# VIMS register map
Vendor: Texas Instruments
Peripheral module from a debugger description file (folder CC23x0R5).
Registers are 32-bit, access per field, reset 0x7 unless marked. A register's access mark holds for its fields unless they carry their own. Offsets are as the file gives them; lines under a group give offsets from that group; [hi:lo] are bit positions; {n}, {i} and the like mark numbered series; 'fields as' and 'values as' point back to an identical list; <NAME> marks a mode.

## VIMS — VIMS (Versatile Instruction Memory System) All registers in this module are retained, unless explicitely mentioned.
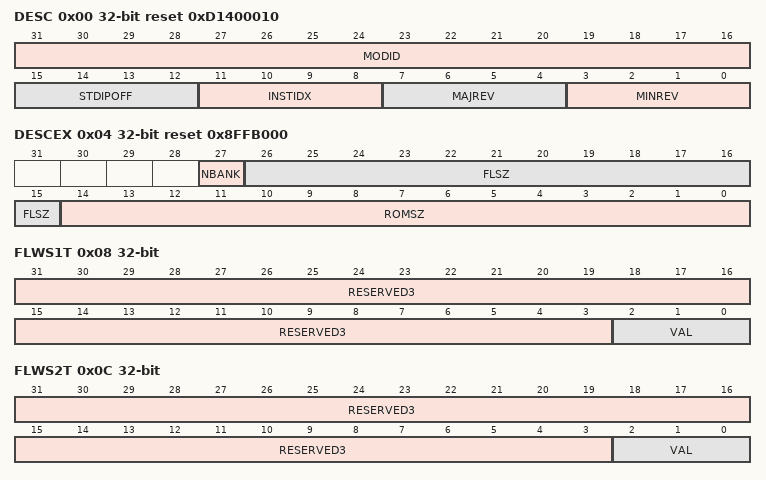
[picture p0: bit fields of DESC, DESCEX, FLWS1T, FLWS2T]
0x00 DESC ro reset 0xD1400010 — Description Register. This register provides IP module ID, revision information, instance index and standard MMR registers offset.
  [31:16] MODID — Module identifier used to uniquely identify this IP.
  [15:12] STDIPOFF — Standard IP MMR block offset. Standard IP MMRs are the set of from aggregated IRQ registers till DTB. 0: Standard IP MMRs do not exist 0x1-0xF: Standard IP MMRs begin at offset of (64*STDIPOFF from the base IP address)
  [11:8] INSTIDX — IP Instance ID number. If multiple instances of IP exist in the device, this field can identify the instance number (0-15).
  [7:4] MAJREV — Major revision of IP (0-15).
  [3:0] MINREV — Minor revision of IP (0-15).
0x04 DESCEX ro reset 0x8FFB000 — Extended Description Register. This register provides configuration details of the IP to software drivers and end users.
  [27] NBANK — Provides the FLASH Bank count
  [26:15] FLSZ — This provides the total FLASH size in Kilo Bytes. The total FLASH size is (FLSZ + 1)KB
  [14:0] ROMSZ — Provides the size of ROM in Bytes.
0x08 FLWS1T — Internal. Only to be used through TI provided API.
  [31:3] RESERVED3 ro — Internal. Only to be used through TI provided API.
  [2:0] VAL rw — Internal. Only to be used through TI provided API.
    {v}=WS{v} (Internal. Only to be used through TI provided API.) (v=0..7)
0x0C FLWS2T — Internal. Only to be used through TI provided API.
  fields as FLWS1T
0x18 PTRMC0 rw reset 0x131A0000 — Internal. Only to be used through TI provided API.
  [31:0] VAL
0x1C B0TRMC1 rw reset 0x0 — Internal. Only to be used through TI provided API.
  [31:0] VAL
0x20 B0TRMC0 rw reset 0x0 — Internal. Only to be used through TI provided API.
  [31:0] VAL
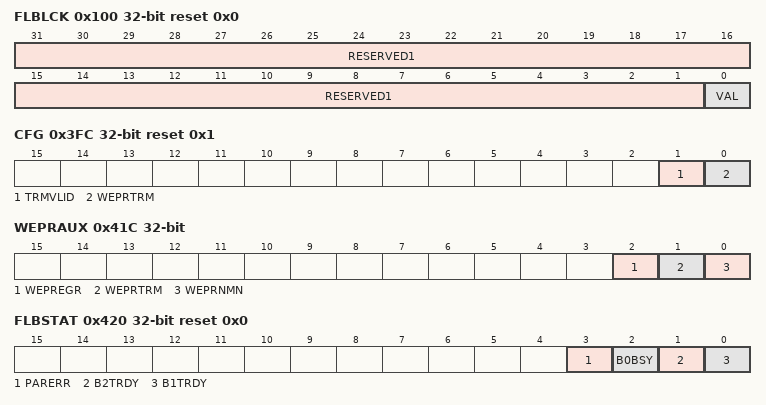
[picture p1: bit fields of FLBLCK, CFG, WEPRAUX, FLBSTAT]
0x100 FLBLCK reset 0x0 — Internal. Only to be used through TI provided API.
  [31:1] RESERVED1 ro — Internal. Only to be used through TI provided API.
  [0] VAL rw — Internal. Only to be used through TI provided API.
    1=BLOCK (Internal. Only to be used through TI provided API.); 0=ALLOW (Internal. Only to be used through TI provided API.)
0x3FC CFG rw reset 0x1 — Internal. Only to be used through TI provided API.
  [1] TRMVLID — Internal. Only to be used through TI provided API.
  [0] WEPRTRM — Internal. Only to be used through TI provided API.
    1=ALLOW (Internal. Only to be used through TI provided API.); 0=RESTRICT (Internal. Only to be used through TI provided API.)
0x410 WEPRA rw reset 0xFFFFFFFF — Flash main region write/erase protection for first 32 sectors. Nth bit corresponds to the Nth sector. This register is sticky when written with value 0.
  [31:0] VAL — Flash write/erase protection configuration value.
0x414 WEPRB reset 0xFFFFFFF — Flash main region write/erase protection for remaining sectors. Each bit corresponds to 8 sectors. Bit 0 corresponds to sector 32-39, bit 1 corresponds to sector 40-47 and so on. This register is sticky when written with value 0.
  [27:0] VAL rw — Flash write/erase protection configuration value.
0x41C WEPRAUX — Flash Write/Erase protection for Non-Main, TRIM and ENGR Regions. This register is sticky when written with value 0.
  [2] WEPREGR rw — Flash engr region write/erase protection configuration value.
  [1] WEPRTRM rw — Flash trim region write/erase protection configuration value.
  [0] WEPRNMN rw — Flash non main region write/erase protection configuration value.
0x420 FLBSTAT ro reset 0x0 — This register is used to indicate status of flash. This register is not retained.
  [3] PARERR — This bit indicates parity error on write/erase and read protection MMRs. This bit is sticky when set to 1 by hardware.
    1=ERROR; 0=NOERROR
  [2] B0BSY — This bit indicates if flash is busy.
    1=BUSY; 0=IDLE
  [1] B2TRDY — This bit indicates if flash is ready in 2T mode.
    1=READY; 0=NOTREADY
  [0] B1TRDY — This bit indicates if flash is ready in 1T mode.
    1=READY; 0=NOTREADY
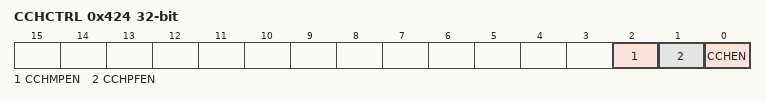
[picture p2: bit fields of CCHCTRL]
0x424 CCHCTRL — This register is used for enabling cache, prefetch and micropredictor units.
  [all] fields
    1=EN (Enable); 0=DIS (Disable)
  [2] CCHMPEN rw — This bit is used to enable the micropredictor unit.
  [1] CCHPFEN rw — This bit is used to enable the prefetch unit.
  [0] CCHEN rw — This bit is used to enable the cache.
